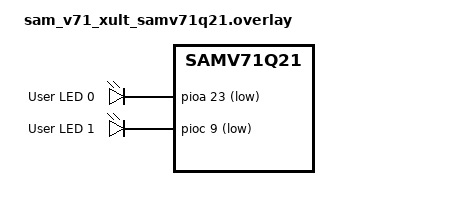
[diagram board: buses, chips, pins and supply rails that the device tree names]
/ {
	aliases {
		led0 = &yellow_led0;
		led1 = &yellow_led1;
		pwmled0 = &pwm_led0;
	};

	leds {
		compatible = "gpio-leds";

		yellow_led0: led_0 {
			gpios = <&pioa 23 GPIO_ACTIVE_LOW>;
			label = "User LED 0";
			status = "okay";
		};

		yellow_led1: led_1 {
			gpios = <&pioc 9 GPIO_ACTIVE_LOW>;
			label = "User LED 1";
			status = "okay";
		};
	};
};	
